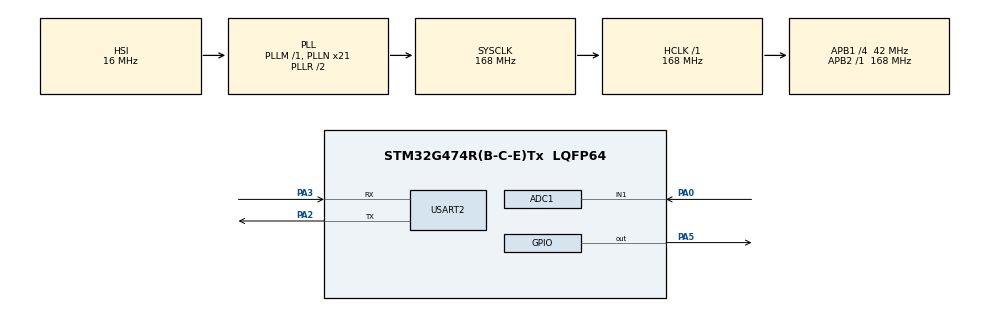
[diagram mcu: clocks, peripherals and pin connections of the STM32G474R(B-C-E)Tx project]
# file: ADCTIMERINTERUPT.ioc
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ADC1.Channel-0\#ChannelRegularConversion=ADC_CHANNEL_1
ADC1.NbrOfConversionFlag=1
ADC1.OffsetNumber-0\#ChannelRegularConversion=ADC_OFFSET_NONE
ADC1.Rank-0\#ChannelRegularConversion=1
ADC1.SamplingTime-0\#ChannelRegularConversion=ADC_SAMPLETIME_2CYCLES_5
ADC1.master=1
Mcu.Family=STM32G4
Mcu.Name=STM32G474R(B-C-E)Tx
Mcu.Package=LQFP64
NVIC.PriorityGroup=NVIC_PRIORITYGROUP_4
NVIC.TIM2_IRQn=true\:0\:0\:false\:false\:true\:true\:true\:true
PA0.Mode=IN1-Single-Ended
PA0.Signal=ADC1_IN1
PA2.Mode=Asynchronous
PA2.Signal=USART2_TX
PA3.Mode=Asynchronous
PA3.Signal=USART2_RX
PA5.Signal=GPIO_Output
ProjectManager.HeapSize=0x200
ProjectManager.StackSize=0x400
ProjectManager.TargetToolchain=STM32CubeIDE
RCC.ADC12Freq_Value=168000000
RCC.ADC345Freq_Value=168000000
RCC.AHBFreq_Value=168000000
RCC.APB1CLKDivider=RCC_HCLK_DIV4
RCC.APB1Freq_Value=42000000
RCC.APB1TimFreq_Value=84000000
RCC.APB2Freq_Value=168000000
RCC.APB2TimFreq_Value=168000000
RCC.CortexFreq_Value=168000000
RCC.EXTERNAL_CLOCK_VALUE=12288000
RCC.HCLKFreq_Value=168000000
RCC.HSE_VALUE=24000000
RCC.HSI48_VALUE=48000000
RCC.HSI_VALUE=16000000
RCC.LSE_VALUE=32768
RCC.PLLN=21
RCC.RTCClockSelection=RCC_RTCCLKSOURCE_LSE
RCC.SYSCLKFreq_VALUE=168000000
RCC.SYSCLKSource=RCC_SYSCLKSOURCE_PLLCLK
RCC.USBFreq_Value=168000000
RCC.VCOOutputFreq_Value=336000000
TIM2.PeriodNoDither=49999
TIM2.Prescaler=8399
USART2.VirtualMode-Asynchronous=VM_ASYNC
VP_SYS_VS_DBSignals.Mode=DisableDeadBatterySignals
VP_TIM2_VS_ClockSourceINT.Mode=Internal
board=NUCLEO-G474RE

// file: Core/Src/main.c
/* USER CODE BEGIN Header */
/**
  ******************************************************************************
  * @file           : main.c
  * @brief          : Main program body
  ******************************************************************************
  * @attention
  *
  * Copyright (c) 2025 STMicroelectronics.
  * All rights reserved.
  *
  * This software is licensed under terms that can be found in the LICENSE file
  * in the root directory of this software component.
  * If no LICENSE file comes with this software, it is provided AS-IS.
  *
  ******************************************************************************
  */
/* USER CODE END Header */
#include "main.h"

/* USER CODE BEGIN Includes */
#include <string.h>
#include <stdio.h>
#include "stm32g474xx.h"
/* USER CODE END Includes */

ADC_HandleTypeDef hadc1;

TIM_HandleTypeDef htim2;

UART_HandleTypeDef huart2;

/* USER CODE BEGIN PV */
uint8_t abc=0;
/* USER CODE END PV */

void SystemClock_Config(void);
static void MX_GPIO_Init(void);
static void MX_ADC1_Init(void);
static void MX_TIM2_Init(void);
static void MX_USART2_UART_Init(void);
/* USER CODE BEGIN PFP */
void HAL_TIM_PeriodElapsedCallback();
/* USER CODE END PFP */

int main(void)
{

  /* MCU Configuration--------------------------------------------------------*/

  /* Reset of all peripherals, Initializes the Flash interface and the Systick. */
  HAL_Init();

  /* Configure the system clock */
  SystemClock_Config();

  /* Initialize all configured peripherals */
  MX_GPIO_Init();
  MX_ADC1_Init();
  MX_TIM2_Init();
  MX_USART2_UART_Init();

  /* Infinite loop */
  while (1)
  {

  }
}

void SystemClock_Config(void)
{
  RCC_OscInitTypeDef RCC_OscInitStruct = {0};
  RCC_ClkInitTypeDef RCC_ClkInitStruct = {0};

  /** Configure the main internal regulator output voltage
  */
  HAL_PWREx_ControlVoltageScaling(PWR_REGULATOR_VOLTAGE_SCALE1_BOOST);

  /** Initializes the RCC Oscillators according to the specified parameters
  * in the RCC_OscInitTypeDef structure.
  */
  RCC_OscInitStruct.OscillatorType = RCC_OSCILLATORTYPE_HSI;
  RCC_OscInitStruct.HSIState = RCC_HSI_ON;
  RCC_OscInitStruct.HSICalibrationValue = RCC_HSICALIBRATION_DEFAULT;
  RCC_OscInitStruct.PLL.PLLState = RCC_PLL_ON;
  RCC_OscInitStruct.PLL.PLLSource = RCC_PLLSOURCE_HSI;
  RCC_OscInitStruct.PLL.PLLM = RCC_PLLM_DIV1;
  RCC_OscInitStruct.PLL.PLLN = 21;
  RCC_OscInitStruct.PLL.PLLP = RCC_PLLP_DIV2;
  RCC_OscInitStruct.PLL.PLLQ = RCC_PLLQ_DIV2;
  RCC_OscInitStruct.PLL.PLLR = RCC_PLLR_DIV2;
  if (HAL_RCC_OscConfig(&RCC_OscInitStruct) != HAL_OK)
  {
    Error_Handler();
  }

  /** Initializes the CPU, AHB and APB buses clocks
  */
  RCC_ClkInitStruct.ClockType = RCC_CLOCKTYPE_HCLK|RCC_CLOCKTYPE_SYSCLK
                              |RCC_CLOCKTYPE_PCLK1|RCC_CLOCKTYPE_PCLK2;
  RCC_ClkInitStruct.SYSCLKSource = RCC_SYSCLKSOURCE_PLLCLK;
  RCC_ClkInitStruct.AHBCLKDivider = RCC_SYSCLK_DIV1;
  RCC_ClkInitStruct.APB1CLKDivider = RCC_HCLK_DIV4;
  RCC_ClkInitStruct.APB2CLKDivider = RCC_HCLK_DIV1;

  if (HAL_RCC_ClockConfig(&RCC_ClkInitStruct, FLASH_LATENCY_4) != HAL_OK)
  {
    Error_Handler();
  }
}

static void MX_ADC1_Init(void)
{

  ADC_MultiModeTypeDef multimode = {0};
  ADC_ChannelConfTypeDef sConfig = {0};

  /** Common config
  */
  hadc1.Instance = ADC1;
  hadc1.Init.ClockPrescaler = ADC_CLOCK_SYNC_PCLK_DIV4;
  hadc1.Init.Resolution = ADC_RESOLUTION_12B;
  hadc1.Init.DataAlign = ADC_DATAALIGN_RIGHT;
  hadc1.Init.GainCompensation = 0;
  hadc1.Init.ScanConvMode = ADC_SCAN_DISABLE;
  hadc1.Init.EOCSelection = ADC_EOC_SINGLE_CONV;
  hadc1.Init.LowPowerAutoWait = DISABLE;
  hadc1.Init.ContinuousConvMode = DISABLE;
  hadc1.Init.NbrOfConversion = 1;
  hadc1.Init.DiscontinuousConvMode = DISABLE;
  hadc1.Init.ExternalTrigConv = ADC_SOFTWARE_START;
  hadc1.Init.ExternalTrigConvEdge = ADC_EXTERNALTRIGCONVEDGE_NONE;
  hadc1.Init.DMAContinuousRequests = DISABLE;
  hadc1.Init.Overrun = ADC_OVR_DATA_PRESERVED;
  hadc1.Init.OversamplingMode = DISABLE;
  if (HAL_ADC_Init(&hadc1) != HAL_OK)
  {
    Error_Handler();
  }

  /** Configure the ADC multi-mode
  */
  multimode.Mode = ADC_MODE_INDEPENDENT;
  if (HAL_ADCEx_MultiModeConfigChannel(&hadc1, &multimode) != HAL_OK)
  {
    Error_Handler();
  }

  /** Configure Regular Channel
  */
  sConfig.Channel = ADC_CHANNEL_1;
  sConfig.Rank = ADC_REGULAR_RANK_1;
  sConfig.SamplingTime = ADC_SAMPLETIME_2CYCLES_5;
  sConfig.SingleDiff = ADC_SINGLE_ENDED;
  sConfig.OffsetNumber = ADC_OFFSET_NONE;
  sConfig.Offset = 0;
  if (HAL_ADC_ConfigChannel(&hadc1, &sConfig) != HAL_OK)
  {
    Error_Handler();
  }

}

static void MX_TIM2_Init(void)
{

  TIM_ClockConfigTypeDef sClockSourceConfig = {0};
  TIM_MasterConfigTypeDef sMasterConfig = {0};

  htim2.Instance = TIM2;
  htim2.Init.Prescaler = 8399;
  htim2.Init.CounterMode = TIM_COUNTERMODE_UP;
  htim2.Init.Period = 49999;
  htim2.Init.ClockDivision = TIM_CLOCKDIVISION_DIV1;
  htim2.Init.AutoReloadPreload = TIM_AUTORELOAD_PRELOAD_DISABLE;
  if (HAL_TIM_Base_Init(&htim2) != HAL_OK)
  {
    Error_Handler();
  }
  sClockSourceConfig.ClockSource = TIM_CLOCKSOURCE_INTERNAL;
  if (HAL_TIM_ConfigClockSource(&htim2, &sClockSourceConfig) != HAL_OK)
  {
    Error_Handler();
  }
  sMasterConfig.MasterOutputTrigger = TIM_TRGO_RESET;
  sMasterConfig.MasterSlaveMode = TIM_MASTERSLAVEMODE_DISABLE;
  if (HAL_TIMEx_MasterConfigSynchronization(&htim2, &sMasterConfig) != HAL_OK)
  {
    Error_Handler();
  }
  /* USER CODE BEGIN TIM2_Init 2 */
  HAL_TIM_Base_Start_IT(&htim2);
  /* USER CODE END TIM2_Init 2 */

}

static void MX_USART2_UART_Init(void)
{

  huart2.Instance = USART2;
  huart2.Init.BaudRate = 115200;
  huart2.Init.WordLength = UART_WORDLENGTH_8B;
  huart2.Init.StopBits = UART_STOPBITS_1;
  huart2.Init.Parity = UART_PARITY_NONE;
  huart2.Init.Mode = UART_MODE_TX_RX;
  huart2.Init.HwFlowCtl = UART_HWCONTROL_NONE;
  huart2.Init.OverSampling = UART_OVERSAMPLING_16;
  huart2.Init.OneBitSampling = UART_ONE_BIT_SAMPLE_DISABLE;
  huart2.Init.ClockPrescaler = UART_PRESCALER_DIV1;
  huart2.AdvancedInit.AdvFeatureInit = UART_ADVFEATURE_NO_INIT;
  if (HAL_UART_Init(&huart2) != HAL_OK)
  {
    Error_Handler();
  }
  if (HAL_UARTEx_SetTxFifoThreshold(&huart2, UART_TXFIFO_THRESHOLD_1_8) != HAL_OK)
  {
    Error_Handler();
  }
  if (HAL_UARTEx_SetRxFifoThreshold(&huart2, UART_RXFIFO_THRESHOLD_1_8) != HAL_OK)
  {
    Error_Handler();
  }
  if (HAL_UARTEx_DisableFifoMode(&huart2) != HAL_OK)
  {
    Error_Handler();
  }

}

static void MX_GPIO_Init(void)
{
  GPIO_InitTypeDef GPIO_InitStruct = {0};

  /* GPIO Ports Clock Enable */
  __HAL_RCC_GPIOA_CLK_ENABLE();

  /*Configure GPIO pin Output Level */
  HAL_GPIO_WritePin(GPIOA, GPIO_PIN_5, GPIO_PIN_RESET);

  /*Configure GPIO pin : PA5 */
  GPIO_InitStruct.Pin = GPIO_PIN_5;
  GPIO_InitStruct.Mode = GPIO_MODE_OUTPUT_PP;
  GPIO_InitStruct.Pull = GPIO_NOPULL;
  GPIO_InitStruct.Speed = GPIO_SPEED_FREQ_LOW;
  HAL_GPIO_Init(GPIOA, &GPIO_InitStruct);

}

/* USER CODE BEGIN 4 */
void HAL_TIM_PeriodElapsedCallback(TIM_HandleTypeDef *htim)
{
    if (htim->Instance == TIM2)
    {
        HAL_ADC_Start(&hadc1);
        HAL_ADC_PollForConversion(&hadc1, HAL_MAX_DELAY);
        uint32_t abc = HAL_ADC_GetValue(&hadc1);

        char msg[50];
        sprintf(msg, "ADC Value: %lu\r\n", abc);
        HAL_UART_Transmit(&huart2, (uint8_t*)msg, strlen(msg), HAL_MAX_DELAY);
    }
}

/* USER CODE END 4 */

void Error_Handler(void)
{
  __disable_irq();
  while (1)
  {
  }
}
